# PIC32CM2532JH01064 register map
Vendor: Microchip Technology; Series: PIC32CMJH01; File version: 0
Microchip PIC32CM2532JH01064 Microcontroller
CPU: CM0+ r0p0, selectable endian, MPU, VTOR, 2 interrupt priority bits, 32 interrupts
Registers are 32-bit, read-write, reset 0x0 unless marked. A register's access mark holds for its fields unless they carry their own. Offsets are from the block's base; lines under a group give offsets from that group; [hi:lo] are bit positions; {n}, {i} and the like mark numbered series; 'fields as' and 'values as' point back to an identical list; <NAME> marks a mode.

## Memory map
0x40000000 PAC size 0x44 — Peripheral Access Controller
0x40000400 PM size 0xA — Power Manager
0x40000800 MCLK size 0x24 — Main Clock
0x40000C00 RSTC size 0x1 — Reset Controller
0x40001000 OSCCTRL size 0x3C — Oscillators Control
0x40001400 OSC32KCTRL size 0x20 — 32k Oscillators Control
0x40001800 SUPC size 0x20 — Supply Controller
0x40001C00 GCLK size 0x18C — Generic Clock Generator
0x40002000 WDT size 0xD — Watchdog Timer
0x40002400 RTC size 0x48 — Real-Time Counter
0x40002800 EIC size 0x3C — External Interrupt Controller
0x40002C00 FREQM size 0x14 — Frequency Meter
0x40003000 MCRAMC size 0x2C — Multi-Channel RAM Controller
0x41000000 PORT size 0x100 — Port Module
0x41002000 DSU size 0x2000 — Device Service Unit
0x41002100 DSU_EXT size 0x2000
0x41004000 NVMCTRL size 0x9D — Non-Volatile Memory Controller
0x41006000 DMAC size 0x50 — Direct Memory Access Controller
0x41008000 MTB size 0x1000 — Cortex-M0+ Micro-Trace Buffer
0x42000000 EVSYS size 0x1C4 — Event System Interface
0x42000400 SERCOM0 size 0x31 — Serial Communication Interface
0x42000800 SERCOM1 size 0x31
0x42000C00 SERCOM2 size 0x31
0x42001000 SERCOM3 size 0x31
0x42001400 SERCOM4 size 0x31
0x42001800 SERCOM5 size 0x31
0x42001C00 CAN0 size 0xFC — Control Area Network
0x42002000 CAN1 size 0xFC
0x42002400 TCC0 size 0x80 — Timer Counter for Control Applications
0x42002800 TCC1 size 0x80
0x42002C00 TCC2 size 0x80
0x42003000 TC0 size 0x38 — Basic Timer Counter
0x42003400 TC1 size 0x38
0x42003800 TC2 size 0x38
0x42003C00 TC3 size 0x38
0x42004000 TC4 size 0x38
0x42004400 ADC0 size 0x2E — Analog Digital Converter
0x42004800 ADC1 size 0x2E
0x42004C00 AC size 0x24 — Analog Comparators
0x42005000 DAC size 0x15 — Digital Analog Converter
0x42005800 CCL size 0x18 — Configurable Custom Logic
0x42006400 ICM size 0x58 — Integrity Check Monitor
0x42006800 PDEC size 0x38 — Quadrature Decodeur
0x42006C00 SMBIST size 0x8 — SRAM MBIST Interface
0x43000800 TC5 size 0x38
0x43000C00 TC6 size 0x38
0x43001000 TC7 size 0x38
0x48000000 DIVAS size 0x1C — Divide and Square Root Accelerator
0x60000000 PORT_IOBUS size 0x100
0x60000200 DIVAS_IOBUS size 0x1C
0xE000E000 SystemControl size 0xD34 — System Control Registers
0xE000E010 SysTick size 0x10 — System timer
0xE000E100 NVIC size 0x320 — Nested Vectored Interrupt Controller
0xE000ED90 MPU size 0x14 — Memory Protection Unit

## Interrupts
1 WDT — Watchdog Timer
2 RTC — Real Time Counter
3 EIC — External Interrupt Controller
4 FREQM — Frequency Meter
5 MCRAMC — SRAM Memory Controller
6 NVMCTRL — Non-Volatile Memory Controller
7 DMAC — Direct Memory Access Controller
8 EVSYS — Event Systems
9 SERCOM0 — Serial Communication Interface 0
10 SERCOM1 — Serial Communication Interface 1
11 SERCOM2 — Serial Communication Interface 2
12 SERCOM3 — Serial Communication Interface 3
13 SERCOM4 — Serial Communication Interface 4
14 SERCOM5 — Serial Communication Interface 5
15 CAN0 — Control Area Network 0
16 CAN1 — Control Area Network 1
17 TCC0 — Timer/Counter for Control Applications 0
18 TCC1 — Timer/Counter for Control Applications 1
19 TCC2 — Timer/Counter for Control Applications 2
23 TC3 — Timer/Counter 3
24 TC4 — Timer/Counter 4
25 ADC0 — Analog-to-Digital Converter 0
26 ADC1 — Analog-to-Digital Converter 1
27 AC — Analog Comparators
28 DAC — Digital-to-Analog Converter
29 PDEC — Position Decoder
31 ICM — Integrity Check Monitor

## CCL — Configurable Custom Logic
Base 0x42005800
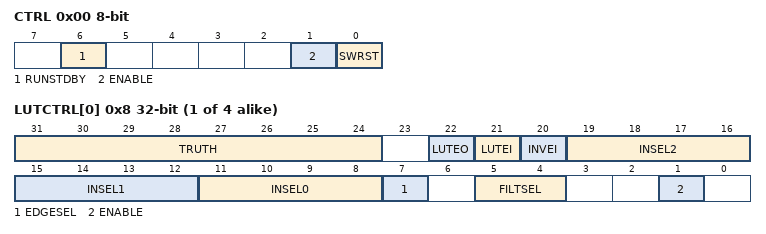
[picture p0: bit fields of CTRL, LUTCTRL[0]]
0x00 CTRL 8-bit — Control
  [6] RUNSTDBY — Run in Standby
    0=DISABLE (Generic clock is not required in standby sleep mode); 1=ENABLE (Generic clock is required in standby sleep mode)
  [1] ENABLE
    0=DISABLE (The peripheral is disabled); 1=ENABLE (The peripheral is enabled)
  [0] SWRST — Software Reset
    0=DISABLE (The peripheral is not reset); 1=ENABLE (The peripheral is reset)
{0x4+i} SEQCTRL[{i}] (i=0..1) 8-bit — SEQ Control x
  [3:0] SEQSEL — Sequential Selection
    0=DISABLE (Sequential logic is disabled); 1=DFF (D flip flop); 2=JK (JK flip flop); 3=LATCH (D latch); 4=RS (RS latch)
{0x8+4i} LUTCTRL[{i}] (i=0..3) — LUT Control x
  [31:24] TRUTH — Truth Value
  [22] LUTEO — LUT Event Output Enable
    0=DISABLE (LUT event output is disabled); 1=ENABLE (LUT event output is enabled)
  [21] LUTEI — LUT Event Input Enable
    0=DISABLE (LUT incoming event is disabled); 1=ENABLE (LUT incoming event is enabled)
  [20] INVEI — Inverted Event Input Enable
    0=NORMAL (Incoming event is not inverted); 1=INVERTED (Incoming event is inverted)
  [19:16] INSEL2 — Input Selection 2
    0=MASK (Masked input); 1=FEEDBACK (Feedback input source); 2=LINK (Linked LUT input source); 3=EVENT (Event input source); 4=IO (I/O pin input source); 5=AC (AC input source); 6=TC (TC input source); 7=ALTTC (Alternate TC input source); 8=TCC (TCC input source); 9=SERCOM (SERCOM input source); 10=ALT2TC (Second alternative TC input source); 11=ASYNCEVENT (Asynchronous event input source)
  [15:12] INSEL1 — Input Selection 1
    values as INSEL2
  [11:8] INSEL0 — Input Selection 0
    values as INSEL2
  [7] EDGESEL — Edge Selection
    0=DISABLE (Edge detector is disabled); 1=ENABLE (Edge detector is enabled)
  [5:4] FILTSEL — Filter Selection
    0=DISABLE (Filter disabled); 1=SYNCH (Synchronizer enabled); 2=FILTER (Filter enabled)
  [1] ENABLE — LUT Enable
    0=DISABLE (LUT block is disabled); 1=ENABLE (LUT block is enabled)

## Notices in the file
Copyright (c) 2023 Microchip Technology Inc.
SPDX-License-Identifier: Apache-2.0
Licensed under the Apache License, Version 2.0 (the "License");
you may not use this file except in compliance with the License.
You may obtain a copy of the License at
http://www.apache.org/licenses/LICENSE-2.0
Unless required by applicable law or agreed to in writing, software
distributed under the License is distributed on an "AS IS" BASIS,
WITHOUT WARRANTIES OR CONDITIONS OF ANY KIND, either express or implied.
See the License for the specific language governing permissions and
limitations under the License.
